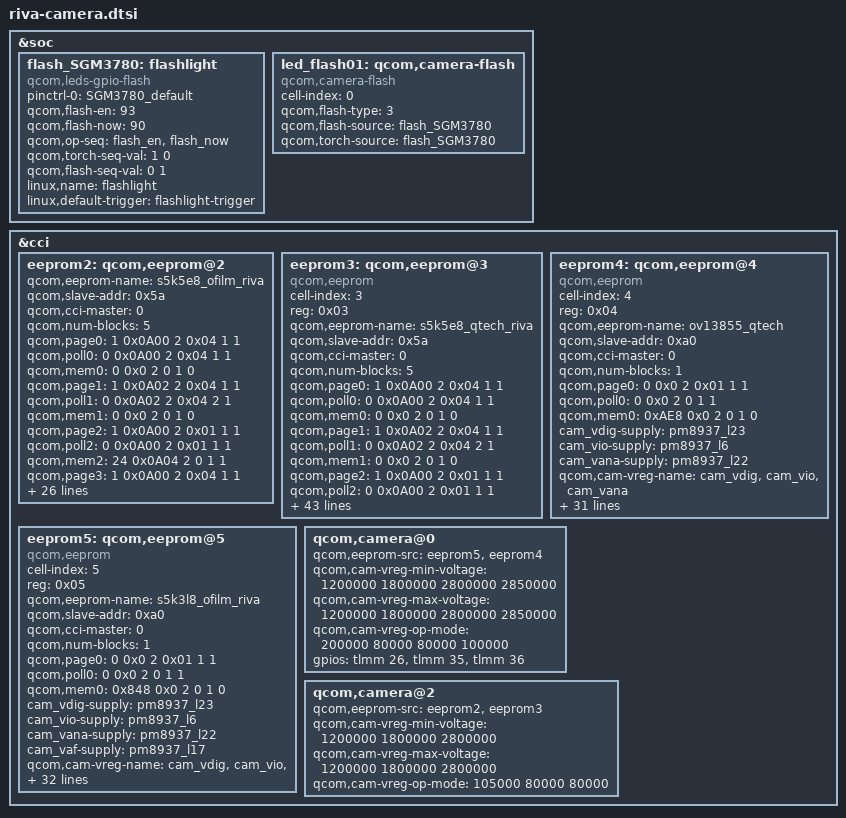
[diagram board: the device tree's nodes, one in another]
/*
 * Copyright (c) 2016, The Linux Foundation. All rights reserved.
 *
 * This program is free software; you can redistribute it and/or modify
 * it under the terms of the GNU General Public License version 2 and
 * only version 2 as published by the Free Software Foundation.
 *
 * This program is distributed in the hope that it will be useful,
 * but WITHOUT ANY WARRANTY; without even the implied warranty of
 * MERCHANTABILITY or FITNESS FOR A PARTICULAR PURPOSE.  See the
 * GNU General Public License for more details.
 */

&soc {
	flash_SGM3780:flashlight {
		compatible = "qcom,leds-gpio-flash";
		status = "okay";
		pinctrl-names = "flash_default";
		pinctrl-0 = <&SGM3780_default>;
		qcom,flash-en = <93>;
		qcom,flash-now = <90>;
		qcom,op-seq = "flash_en", "flash_now";
		qcom,torch-seq-val = <1 0>;
		qcom,flash-seq-val = <0 1>;
		linux,name = "flashlight";
		linux,default-trigger = "flashlight-trigger";
	};
	led_flash01: qcom,camera-flash {
		cell-index = <0>;
		compatible = "qcom,camera-flash";
		qcom,flash-type = <3>;
		qcom,flash-source = <&flash_SGM3780>;
		qcom,torch-source = <&flash_SGM3780>;
	};
};

&cci {
	/delete-node/ qcom,eeprom@0;

	eeprom2: qcom,eeprom@2 {
		qcom,eeprom-name = "s5k5e8_ofilm_riva";
		qcom,slave-addr = <0x5a>;
		qcom,cci-master = <0>;

		qcom,num-blocks = <5>;
		qcom,page0 = <1 0x0A00 2 0x04 1 1>;
		qcom,poll0 = <0 0x0A00 2 0x04 1 1>;
		qcom,mem0 = <0 0x0 2 0 1 0>;
		qcom,page1 = <1 0x0A02 2 0x04 1 1>;
		qcom,poll1 = <0 0x0A02 2 0x04 2 1>;
		qcom,mem1 = <0 0x0 2 0 1 0>;
		qcom,page2 = <1 0x0A00 2 0x01 1 1>;
		qcom,poll2 = <0 0x0A00 2 0x01 1 1>;
		qcom,mem2 = <24 0x0A04 2 0 1 1>;
		qcom,page3 = <1 0x0A00 2 0x04 1 1>;
		qcom,poll3 = <0 0x0A00 2 0x04 1 1>;
		qcom,mem3 = <0 0x0 2 0 1 0>;
		qcom,page4 = <1 0x0A00 2 0x00 1 1>;
		qcom,poll4 =   <0 0x0A00 2 0x00 1 0>;
		qcom,mem4 = <0 0x0 2 0 1 0>;

		/delete-property/ cam_vaf-supply;

		qcom,cam-vreg-name = "cam_vdig", "cam_vio", "cam_vana";
		qcom,cam-vreg-min-voltage = <1200000 1800000 2800000>;
		qcom,cam-vreg-max-voltage = <1200000 1800000 2800000>;
		qcom,cam-vreg-op-mode = <200000 80000 100000>;
		qcom,cam-power-seq-type =
			"sensor_gpio",
			"sensor_gpio",
			"sensor_clk",
			"sensor_vreg",
			"sensor_vreg",
			"sensor_vreg",
			"sensor_gpio",
			"sensor_gpio";
		qcom,cam-power-seq-val =
			"sensor_gpio_reset",
			"sensor_gpio_standby",
			"sensor_cam_mclk",
			"cam_vdig",
			"cam_vana",
			"cam_vio",
			"sensor_gpio_reset",
			"sensor_gpio_standby";

			
		qcom,cam-power-seq-cfg-val = <0 0 24000000 1 1 1 1 1>;
		qcom,cam-power-seq-delay = <1 5 1 1 1 1 1 1 10>;
		status = "ok";
		clocks = <&clock_gcc clk_mclk2_clk_src>,
			<&clock_gcc clk_gcc_camss_mclk2_clk>;
		clock-names = "cam_src_clk", "cam_clk";
		qcom,clock-rates = <24000000 0>;
	};

	eeprom3: qcom,eeprom@3 {
		cell-index = <3>;
		reg = <0x03>;
		qcom,eeprom-name = "s5k5e8_qtech_riva";
		compatible = "qcom,eeprom";
		qcom,slave-addr = <0x5a>;
		qcom,cci-master = <0>;

		qcom,num-blocks = <5>;
		qcom,page0 = <1 0x0A00 2 0x04 1 1>;
		qcom,poll0 = <0 0x0A00 2 0x04 1 1>;
		qcom,mem0 = <0 0x0 2 0 1 0>;
		qcom,page1 = <1 0x0A02 2 0x04 1 1>;
		qcom,poll1 = <0 0x0A02 2 0x04 2 1>;
		qcom,mem1 = <0 0x0 2 0 1 0>;
		qcom,page2 = <1 0x0A00 2 0x01 1 1>;
		qcom,poll2 = <0 0x0A00 2 0x01 1 1>;
		qcom,mem2 = <24 0x0A04 2 0 1 1>;
		qcom,page3 = <1 0x0A00 2 0x04 1 1>;
		qcom,poll3 = <0 0x0A00 2 0x04 1 1>;
		qcom,mem3 = <0 0x0 2 0 1 0>;
		qcom,page4 = <1 0x0A00 2 0x00 1 1>;
		qcom,poll4 =   <0 0x0A00 2 0x00 1 0>;
		qcom,mem4 = <0 0x0 2 0 1 0>;

		cam_vdig-supply = <&pm8937_l23>;
		cam_vana-supply = <&pm8937_l22>;
		cam_vio-supply = <&pm8937_l6>;
		qcom,cam-vreg-name = "cam_vdig", "cam_vio", "cam_vana";
		qcom,cam-vreg-min-voltage = <1200000 1800000 2800000>;
		qcom,cam-vreg-max-voltage = <1200000 1800000 2800000>;
		qcom,cam-vreg-op-mode = <200000 80000 100000>;
		qcom,gpio-no-mux = <0>;
		pinctrl-names = "cam_default", "cam_suspend";
		pinctrl-0 = <&cam_sensor_mclk2_default
					&cam_sensor_front1_default>;
		pinctrl-1 = <&cam_sensor_mclk2_sleep
					&cam_sensor_front1_sleep>;
		gpios = <&tlmm 28 0>,
			<&tlmm 40 0>,
			<&tlmm 39 0>;
		qcom,gpio-reset = <1>;
		qcom,gpio-standby = <2>;
		qcom,gpio-req-tbl-num = <0 1 2>;
		qcom,gpio-req-tbl-flags = <1 0 0>;
		qcom,gpio-req-tbl-label = "CAMIF_MCLK2",
					"CAM_RESET2",
					"CAM_STANDBY2";
		qcom,cam-power-seq-type =
			"sensor_gpio",
			"sensor_gpio",
			"sensor_clk",
			"sensor_vreg",
			"sensor_vreg",
			"sensor_vreg",
			"sensor_gpio",
			"sensor_gpio";
		qcom,cam-power-seq-val =
			"sensor_gpio_reset",
			"sensor_gpio_standby",
			"sensor_cam_mclk",
			"cam_vdig",
			"cam_vana",
			"cam_vio",
			"sensor_gpio_reset",
			"sensor_gpio_standby";
		qcom,cam-power-seq-cfg-val = <0 0 24000000 1 1 1 1 1>;
		qcom,cam-power-seq-delay = <1 5 1 1 1 1 1 1 10>;
		status = "ok";
		clocks = <&clock_gcc clk_mclk2_clk_src>,
			<&clock_gcc clk_gcc_camss_mclk2_clk>;
		clock-names = "cam_src_clk", "cam_clk";
		qcom,clock-rates = <24000000 0>;
	};

	eeprom4: qcom,eeprom@4 {
		cell-index = <4>;
		reg = <0x04>;
		qcom,eeprom-name = "ov13855_qtech";
		compatible = "qcom,eeprom";
		qcom,slave-addr = <0xa0>;
		qcom,cci-master = <0>;
		qcom,num-blocks = <1>;

		qcom,page0 = <0 0x0 2 0x01 1 1>;
		qcom,poll0 = <0 0x0 2 0 1 1>;
		qcom,mem0 = <0xAE8 0x0 2 0 1 0>;

		cam_vdig-supply = <&pm8937_l23>;
		cam_vio-supply = <&pm8937_l6>;
		cam_vana-supply = <&pm8937_l22>;
		qcom,cam-vreg-name = "cam_vdig", "cam_vio", "cam_vana";
		qcom,cam-vreg-min-voltage = <1200000 1800000 2800000>;
		qcom,cam-vreg-max-voltage = <1200000 1800000 2800000>;
		qcom,cam-vreg-op-mode = <200000 80000 100000>;
		qcom,gpio-no-mux = <0>;
		pinctrl-names = "cam_default", "cam_suspend";
		pinctrl-0 = <&cam_sensor_mclk2_default
					&cam_sensor_front1_default>;
		pinctrl-1 = <&cam_sensor_mclk2_sleep
					&cam_sensor_front1_sleep>;
		gpios = <&tlmm 28 0>,
			<&tlmm 40 0>,
			<&tlmm 39 0>;
		qcom,gpio-reset = <1>;
		qcom,gpio-standby = <2>;
		qcom,gpio-req-tbl-num = <0 1 2>;
		qcom,gpio-req-tbl-flags = <1 0 0>;
		qcom,gpio-req-tbl-label = "CAMIF_MCLK2",
					"CAM_RESET2",
					"CAM_STANDBY2";
		qcom,cam-power-seq-type =
			"sensor_gpio",
			"sensor_gpio",
			"sensor_clk",
			"sensor_vreg",
			"sensor_vreg",
			"sensor_vreg",
			"sensor_gpio",
			"sensor_gpio";
		qcom,cam-power-seq-val =
			"sensor_gpio_reset",
			"sensor_gpio_standby",
			"sensor_cam_mclk",
			"cam_vdig",
			"cam_vana",
			"cam_vio",
			"sensor_gpio_reset",
			"sensor_gpio_standby";
		qcom,cam-power-seq-cfg-val = <0 0 24000000 1 1 1 1 1>;
		qcom,cam-power-seq-delay = <5 1 1 1 1 1 10 1>;
		status = "ok";
		clocks = <&clock_gcc clk_mclk2_clk_src>,
			<&clock_gcc clk_gcc_camss_mclk2_clk>;
		clock-names = "cam_src_clk", "cam_clk";
		qcom,clock-rates = <24000000 0>;
	};

	eeprom5: qcom,eeprom@5 {
		cell-index = <5>;
		reg = <0x05>;
		qcom,eeprom-name = "s5k3l8_ofilm_riva";
		compatible = "qcom,eeprom";
		qcom,slave-addr = <0xa0>;
		qcom,cci-master = <0>;
		qcom,num-blocks = <1>;

		qcom,page0 = <0 0x0 2 0x01 1 1>;
		qcom,poll0 = <0 0x0 2 0 1 1>;
		qcom,mem0 = <0x848 0x0 2 0 1 0>;

		cam_vdig-supply = <&pm8937_l23>;
		cam_vio-supply = <&pm8937_l6>;
		cam_vana-supply = <&pm8937_l22>;
		cam_vaf-supply = <&pm8937_l17>;
		qcom,cam-vreg-name = "cam_vdig", "cam_vio", "cam_vana",
							"cam_vaf";
		qcom,cam-vreg-min-voltage = <1200000 1800000 2800000 2850000>;
		qcom,cam-vreg-max-voltage = <1200000 1800000 2800000 2850000>;
		qcom,cam-vreg-op-mode = <200000 200000 80000 100000>;
		pinctrl-names = "cam_default", "cam_suspend";
		pinctrl-0 = <&cam_sensor_mclk0_default &cam_sensor_rear_default>;
		pinctrl-1 = <&cam_sensor_mclk0_sleep &cam_sensor_rear_sleep>;
		gpios = <&tlmm 26 0>,
			<&tlmm 35 0>,
			<&tlmm 36 0>;
		qcom,gpio-reset = <1>;
		qcom,gpio-standby = <2>;
		qcom,gpio-req-tbl-num = <0 1 2>;
		qcom,gpio-req-tbl-flags = <1 0 0>;
		qcom,gpio-req-tbl-label = "CAMIF_MCLK0",
			"MCAM_RESET0",
			"MCAM_STANDBY0";
		qcom,cam-power-seq-type =
			"sensor_gpio",
			"sensor_gpio",
			"sensor_clk",
			"sensor_vreg",
			"sensor_vreg",
			"sensor_vreg",
			"sensor_gpio",
			"sensor_gpio";
		qcom,cam-power-seq-val =
			"sensor_gpio_reset",
			"sensor_gpio_standby",
			"sensor_cam_mclk",
			"cam_vdig",
			"cam_vana",
			"cam_vio",
			"sensor_gpio_reset",
			"sensor_gpio_standby";
		qcom,cam-power-seq-cfg-val = <0 0 24000000 1 1 1 1 1>;
		qcom,cam-power-seq-delay = <5 1 1 1 1 1 10 1>;
		status = "ok";
		clocks = <&clock_gcc clk_mclk0_clk_src>,
				<&clock_gcc clk_gcc_camss_mclk0_clk>;
		clock-names = "cam_src_clk", "cam_clk";
		qcom,clock-rates = <24000000 0>;
	};

	qcom,camera@0 {
		qcom,eeprom-src = <&eeprom5 &eeprom4>;
		qcom,cam-vreg-min-voltage = <1200000 1800000 2800000 2850000>;
		qcom,cam-vreg-max-voltage = <1200000 1800000 2800000 2850000>;
		qcom,cam-vreg-op-mode = <200000 80000 80000 100000>;
		gpios = <&tlmm 26 0>,
			<&tlmm 35 0>,
			<&tlmm 36 0>;
	};

	qcom,camera@2 {
		qcom,eeprom-src = <&eeprom2 &eeprom3>;
		qcom,cam-vreg-min-voltage = <1200000 1800000 2800000>;
		qcom,cam-vreg-max-voltage = <1200000 1800000 2800000>;
		qcom,cam-vreg-op-mode = <105000 80000 80000>;
	};
};
